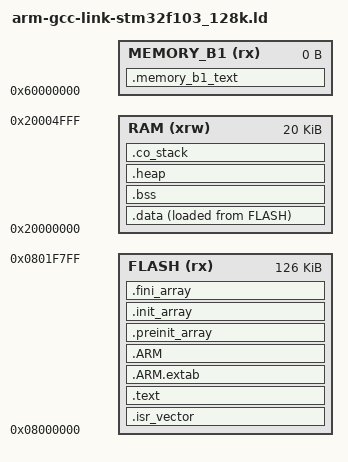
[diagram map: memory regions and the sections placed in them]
/*
*****************************************************************************
**
**  File        : stm32_flash.ld
**
**  Abstract    : Linker script for STM32F103CB Device with
**                128KByte FLASH, 20KByte RAM
**
*****************************************************************************
*/

/* Entry Point */
ENTRY(Reset_Handler)

/* Specify the memory areas. Flash is limited for last 2K for configuration storage */
MEMORY
{
  FLASH (rx)      : ORIGIN = 0x08000000, LENGTH = 126K /* last 2kb used for config storage */
  RAM (xrw)       : ORIGIN = 0x20000000, LENGTH = 20K
  MEMORY_B1 (rx)  : ORIGIN = 0x60000000, LENGTH = 0K
}

/* Define output sections */
_eram = 0x20000000 + 0x00005000;
SECTIONS
{
  /* The startup code goes first into FLASH */
  .isr_vector :
  {
    . = ALIGN(4);
    PROVIDE (isr_vector_table_base = .);
    KEEP(*(.isr_vector)) /* Startup code */
    . = ALIGN(4);
  } >FLASH

  /* The program code and other data goes into FLASH */
  .text :
  {
    . = ALIGN(4);
    *(.text)           /* .text sections (code) */
    *(.text*)          /* .text* sections (code) */
    *(.rodata)         /* .rodata sections (constants, strings, etc.) */
    *(.rodata*)        /* .rodata* sections (constants, strings, etc.) */
    *(.glue_7)         /* glue arm to thumb code */
    *(.glue_7t)        /* glue thumb to arm code */
    *(.eh_frame)

    KEEP (*(.init))
    KEEP (*(.fini))

    . = ALIGN(4);
    _etext = .;        /* define a global symbols at end of code */
  } >FLASH


   .ARM.extab   : { *(.ARM.extab* .gnu.linkonce.armextab.*) } >FLASH
    .ARM : {
    __exidx_start = .;
      *(.ARM.exidx*)
      __exidx_end = .;
    } >FLASH

  .preinit_array     :
  {
    PROVIDE_HIDDEN (__preinit_array_start = .);
    KEEP (*(.preinit_array*))
    PROVIDE_HIDDEN (__preinit_array_end = .);
  } >FLASH
  .init_array :
  {
    PROVIDE_HIDDEN (__init_array_start = .);
    KEEP (*(SORT(.init_array.*)))
    KEEP (*(.init_array*))
    PROVIDE_HIDDEN (__init_array_end = .);
  } >FLASH
  .fini_array :
  {
    PROVIDE_HIDDEN (__fini_array_start = .);
    KEEP (*(.fini_array*))
    KEEP (*(SORT(.fini_array.*)))
    PROVIDE_HIDDEN (__fini_array_end = .);
  } >FLASH

  /* used by the startup to initialize data */
  _sidata = .;

  /* Initialized data sections goes into RAM, load LMA copy after code */
  .data :
  {
    . = ALIGN(4);
    _sdata = .;        /* create a global symbol at data start */
    *(.data)           /* .data sections */
    *(.data*)          /* .data* sections */

    . = ALIGN(4);
    _edata = .;        /* define a global symbol at data end */
  } >RAM AT> FLASH

  /* Uninitialized data section */
  . = ALIGN(4);
  .bss :
  {
    /* This is used by the startup in order to initialize the .bss secion */
    _sbss = .;         /* define a global symbol at bss start */
    __bss_start__ = _sbss;
    *(.bss)
    *(.bss*)
    *(COMMON)

    . = ALIGN(4);
    _ebss = .;         /* define a global symbol at bss end */
    __bss_end__ = _ebss;
  } >RAM

  /* User_heap_stack section, used to check that there is enough RAM left */
	.heap (COPY):
	{
	. = ALIGN(4);
	PROVIDE ( end = . );
		__end__ = .;
		_end = __end__;
		end = __end__;
		*(.heap*)
		__HeapLimit = .;
	. = ALIGN(4);
	} >RAM

	/* .stack_dummy section doesn't contains any symbols. It is only
	* used for linker to calculate size of stack sections, and assign
	* values to stack symbols later */
	.co_stack (NOLOAD):
	{
		. = ALIGN(8);
		*(.co_stack .co_stack.*)
	} > RAM

	/* Set stack top to end of ram , and stack limit move down by
	* size of stack_dummy section */
	__StackTop = ORIGIN(RAM) + LENGTH(RAM);
	__StackLimit = __StackTop - SIZEOF(.co_stack);
	PROVIDE(__stack = __StackTop);

	/* Check if data + heap + stack exceeds ram  limit */
	ASSERT(__StackLimit >= __HeapLimit, "region ram  overflowed with stack")

  /* MEMORY_bank1 section, code must be located here explicitly            */
  /* Example: extern int foo(void) __attribute__ ((section (".mb1text"))); */
  .memory_b1_text :
  {
    *(.mb1text)        /* .mb1text sections (code) */
    *(.mb1text*)       /* .mb1text* sections (code)  */
    *(.mb1rodata)      /* read-only data (constants) */
    *(.mb1rodata*)
  } >MEMORY_B1

  /* Remove information from the standard libraries */
  /DISCARD/ :
  {
    libc.a ( * )
    libm.a ( * )
    libgcc.a ( * )
  }

  .ARM.attributes 0 : { *(.ARM.attributes) }
}
